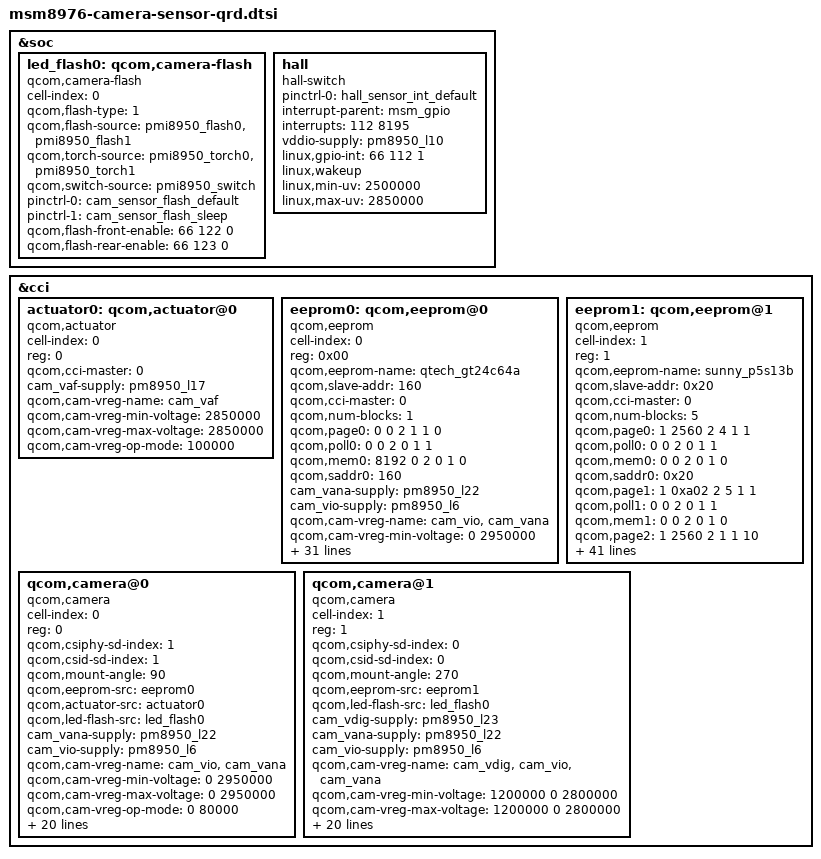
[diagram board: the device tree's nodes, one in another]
/*
 * Copyright (c) 2015, The Linux Foundation. All rights reserved.
 *
 * This program is free software; you can redistribute it and/or modify
 * it under the terms of the GNU General Public License version 2 and
 * only version 2 as published by the Free Software Foundation.
 *
 * This program is distributed in the hope that it will be useful,
 * but WITHOUT ANY WARRANTY; without even the implied warranty of
 * MERCHANTABILITY or FITNESS FOR A PARTICULAR PURPOSE.  See the
 * GNU General Public License for more details.
 */

&soc {
	led_flash0: qcom,camera-flash {
		cell-index = <0>;
		compatible = "qcom,camera-flash";
		qcom,flash-type = <1>;
		qcom,flash-source = <&pmi8950_flash0 &pmi8950_flash1>;
		qcom,torch-source = <&pmi8950_torch0 &pmi8950_torch1>;
		qcom,switch-source = <&pmi8950_switch>;
		pinctrl-names = "cam_default", "cam_suspend";
		pinctrl-0 = <&cam_sensor_flash_default>;
		pinctrl-1 = <&cam_sensor_flash_sleep>;
		qcom,flash-front-enable = <66 122 0>;
		qcom,flash-rear-enable = <66 123 0>;
	};

	hall {
		compatible = "hall-switch";
		pinctrl-names = "default";
		pinctrl-0 = <&hall_sensor_int_default>;
		interrupt-parent = <&msm_gpio>;
		interrupts = <112 8195>;
		vddio-supply = <&pm8950_l10>;
		linux,gpio-int = <66 112 1>;
		linux,wakeup;
		linux,min-uv = <2500000>;
		linux,max-uv = <2850000>;
	};
};

&cci {
	actuator0: qcom,actuator@0 {
		cell-index = <0>;
		reg = <0>;
		compatible = "qcom,actuator";
		qcom,cci-master = <0>;
		cam_vaf-supply = <&pm8950_l17>;
		qcom,cam-vreg-name = "cam_vaf";
		qcom,cam-vreg-min-voltage = <2850000>;
		qcom,cam-vreg-max-voltage = <2850000>;
		qcom,cam-vreg-op-mode = <100000>;
	};

	eeprom0: qcom,eeprom@0 {
		cell-index = <0>;
		reg = <0x00>;
		qcom,eeprom-name = "qtech_gt24c64a";
		compatible = "qcom,eeprom";
		qcom,slave-addr = <160>;
		qcom,cci-master = <0>;
		qcom,num-blocks = <1>;
		qcom,page0 = <0 0 2 1 1 0>;
		qcom,poll0 = <0 0 2 0 1 1>;
		qcom,mem0 = <8192 0 2 0 1 0>;
		qcom,saddr0 = <160>;
		cam_vana-supply = <&pm8950_l22>;
		cam_vio-supply = <&pm8950_l6>;
		qcom,cam-vreg-name = "cam_vio", "cam_vana";
		qcom,cam-vreg-min-voltage = <0 2950000>;
		qcom,cam-vreg-max-voltage = <0 2950000>;
		qcom,cam-vreg-op-mode = <0 80000>;
		pinctrl-names = "cam_default", "cam_suspend";
		pinctrl-0 = <&cam_sensor_mclk0_default &cam_sensor_rear_default>;
		pinctrl-1 = <&cam_sensor_mclk0_sleep &cam_sensor_rear_sleep>;
		gpios = <&msm_gpio 26 0>,
			<&msm_gpio 129 0>,
			<&msm_gpio 35 0>,
			<&msm_gpio 124 0>,
			<&msm_gpio 128 0>;
		qcom,gpio-reset = <1>;
		qcom,gpio-standby = <2>;
		qcom,gpio-vdig = <3>;
		qcom,gpio-vana = <4>;
		qcom,gpio-req-tbl-num = <0 1 2 3 4>;
		qcom,gpio-req-tbl-flags = <1 0 0 0 0>;
		qcom,gpio-req-tbl-label = "MCAM1_MCLK0", "MCAM1_RESET", "MCAM1_STANDBY", "MCAM_GPIO_DVDD", "MCAM_GPIO_AVDD";
		qcom,cam-power-seq-type = "sensor_gpio", "sensor_gpio", "sensor_gpio", "sensor_vreg", "sensor_vreg", "sensor_gpio", "sensor_clk", "sensor_gpio", "sensor_gpio";
		qcom,cam-power-seq-val = "sensor_gpio_reset", "sensor_gpio_standby", "sensor_gpio_vana", "cam_vana", "cam_vio", "sensor_gpio_vdig", "sensor_cam_mclk", "sensor_gpio_reset", "sensor_gpio_standby";
		qcom,cam-power-seq-cfg-val = <0 0 1 1 1 1 24000000 1 1>;
		qcom,cam-power-seq-delay = <5 5 1 1 1 5 5 5 10>;
		status = "ok";
		clocks = <&clock_gcc clk_mclk0_clk_src>,
				<&clock_gcc clk_gcc_camss_mclk0_clk>;
		clock-names = "cam_src_clk", "cam_clk";
	};

	eeprom1: qcom,eeprom@1 {
		cell-index = <1>;
		reg = <1>;
		qcom,eeprom-name = "sunny_p5s13b";
		compatible = "qcom,eeprom";
		qcom,slave-addr = <0x20>;
		qcom,cci-master = <0>;
		qcom,num-blocks = <5>;
		qcom,page0 = <1 2560  2 4 1 1>;
		qcom,poll0 = <0 0 2 0 1 1>;
		qcom,mem0 = <0 0 2 0 1 0>;
		qcom,saddr0 = <0x20>;
		qcom,page1 = <1 0xa02 2 5 1 1>;
		qcom,poll1 = <0 0 2 0 1 1>;
		qcom,mem1 = <0 0 2 0 1 0>;
		qcom,page2 = <1 2560  2 1 1 10>;
		qcom,poll2 = <0 0 2 0 1 1>;
		qcom,mem2 = <0x40 0xa04 2 0 1 0>;
		qcom,page3 = <1 2560  2 4 1 1>;
		qcom,poll3 = <0 0 2 0 1 1>;
		qcom,mem3 = <0 0 2 0 1 1>;
		qcom,page4 = <1 2560 2 0 1 1>;
		qcom,poll4 = <0 0 2 0 1 1>;
		qcom,mem4 = <0 0 2 0 1 0>;
		cam_vdig-supply = <&pm8950_l23>;
		cam_vana-supply = <&pm8950_l22>;
		cam_vio-supply = <&pm8950_l6>;
		qcom,cam-vreg-name = "cam_vdig", "cam_vio", "cam_vana";
		qcom,cam-vreg-min-voltage = <1200000 0 2800000>;
		qcom,cam-vreg-max-voltage = <1200000 0 2800000>;
		qcom,cam-vreg-op-mode = <105000 0 80000>;
		qcom,gpio-no-mux = <0>;
		pinctrl-names = "cam_default", "cam_suspend";
		pinctrl-0 = <&cam_sensor_mclk2_default &cam_sensor_front_default>;
		pinctrl-1 = <&cam_sensor_mclk2_sleep &cam_sensor_front_sleep>;
		gpios = <&msm_gpio 28 0>,
			<&msm_gpio 131 0>,
			<&msm_gpio 38 0>,
			<&msm_gpio 128 0>;
		qcom,gpio-reset = <1>;
		qcom,gpio-standby = <2>;
		qcom,gpio-vana = <3>;
		qcom,gpio-req-tbl-num = <0 1 2 3>;
		qcom,gpio-req-tbl-flags = <1 0 0 0>;
		qcom,gpio-req-tbl-label = "SCAM_MCLK2", "SCAM_RESET", "SCAM_STANDBY";
		qcom,cam-power-seq-type = "sensor_gpio", "sensor_vreg", "sensor_gpio", "sensor_vreg", "sensor_vreg", "sensor_clk", "sensor_gpio";
		qcom,cam-power-seq-val = "sensor_gpio_reset", "cam_vana", "sensor_gpio_vana", "cam_vdig", "cam_vio", "sensor_cam_mclk", "sensor_gpio_reset";
		qcom,cam-power-seq-cfg-val = <0 1 1 1 1 24000000 1>;
		qcom,cam-power-seq-delay = <10 10 10 10 10 10 5>;
		clocks = <&clock_gcc clk_mclk2_clk_src>,
				<&clock_gcc clk_gcc_camss_mclk2_clk>;
		clock-names = "cam_src_clk", "cam_clk";
	};

	qcom,camera@0 {
		cell-index = <0>;
		compatible = "qcom,camera";
		reg = <0>;
		qcom,csiphy-sd-index = <1>;
		qcom,csid-sd-index = <1>;
		qcom,mount-angle = <90>;
		qcom,eeprom-src = <&eeprom0>;
		qcom,actuator-src = <&actuator0>;
		qcom,led-flash-src = <&led_flash0>;
		cam_vana-supply = <&pm8950_l22>;
		cam_vio-supply = <&pm8950_l6>;
		qcom,cam-vreg-name = "cam_vio", "cam_vana";
		qcom,cam-vreg-min-voltage = <0 2950000>;
		qcom,cam-vreg-max-voltage = <0 2950000>;
		qcom,cam-vreg-op-mode = <0 80000>;
		pinctrl-names = "cam_default", "cam_suspend";
		pinctrl-0 = <&cam_sensor_mclk0_default &cam_sensor_rear_default>;
		pinctrl-1 = <&cam_sensor_mclk0_sleep &cam_sensor_rear_sleep>;
		gpios = <&msm_gpio 26 0>,
			<&msm_gpio 129 0>,
			<&msm_gpio 35 0>,
			<&msm_gpio 124 0>,
			<&msm_gpio 128 0>;
		qcom,gpio-reset = <1>;
		qcom,gpio-standby = <2>;
		qcom,gpio-vdig = <3>;
		qcom,gpio-vana = <4>;
		qcom,gpio-req-tbl-num = <0 1 2 3 4>;
		qcom,gpio-req-tbl-flags = <1 0 0 0 0>;
		qcom,gpio-req-tbl-label = "MCAM1_MCLK0", "MCAM1_RESET", "MCAM1_STANDBY", "MCAM_GPIO_DVDD", "MCAM_GPIO_AVDD";
		qcom,sensor-position = <0>;
		qcom,sensor-mode = <0>;
		qcom,cci-master = <0>;
		status = "ok";
		clocks = <&clock_gcc clk_mclk0_clk_src>,
				<&clock_gcc clk_gcc_camss_mclk0_clk>;
		clock-names = "cam_src_clk", "cam_clk";
	};

	qcom,camera@1 {
		cell-index = <1>;
		compatible = "qcom,camera";
		reg = <1>;
		qcom,csiphy-sd-index = <0>;
		qcom,csid-sd-index = <0>;
		qcom,mount-angle = <270>;
		qcom,eeprom-src = <&eeprom1>;
		qcom,led-flash-src = <&led_flash0>;
		cam_vdig-supply = <&pm8950_l23>;
		cam_vana-supply = <&pm8950_l22>;
		cam_vio-supply = <&pm8950_l6>;
		qcom,cam-vreg-name = "cam_vdig", "cam_vio", "cam_vana";
		qcom,cam-vreg-min-voltage = <1200000 0 2800000>;
		qcom,cam-vreg-max-voltage = <1200000 0 2800000>;
		qcom,cam-vreg-op-mode = <105000 0 80000>;
		qcom,gpio-no-mux = <0>;
		pinctrl-names = "cam_default", "cam_suspend";
		pinctrl-0 = <&cam_sensor_mclk2_default &cam_sensor_front_default>;
		pinctrl-1 = <&cam_sensor_mclk2_sleep &cam_sensor_front_sleep>;
		gpios = <&msm_gpio 28 0>,
			<&msm_gpio 131 0>,
			<&msm_gpio 38 0>,
			<&msm_gpio 128 0>;
		qcom,gpio-reset = <1>;
		qcom,gpio-standby = <2>;
		qcom,gpio-vana = <3>;
		qcom,gpio-req-tbl-num = <0 1 2 3>;
		qcom,gpio-req-tbl-flags = <1 0 0 0>;
		qcom,gpio-req-tbl-label = "MCAM2_MCLK2", "MCAM2_RESET", "MCAM2_STANDBY", "MCAM_GPIO_AVDD";
		qcom,sensor-position = <1>;
		qcom,sensor-mode = <0>;
		qcom,cci-master = <0>;
		status = "ok";
		clocks = <&clock_gcc clk_mclk2_clk_src>,
				<&clock_gcc clk_gcc_camss_mclk2_clk>;
		clock-names = "cam_src_clk", "cam_clk";
	};
};
